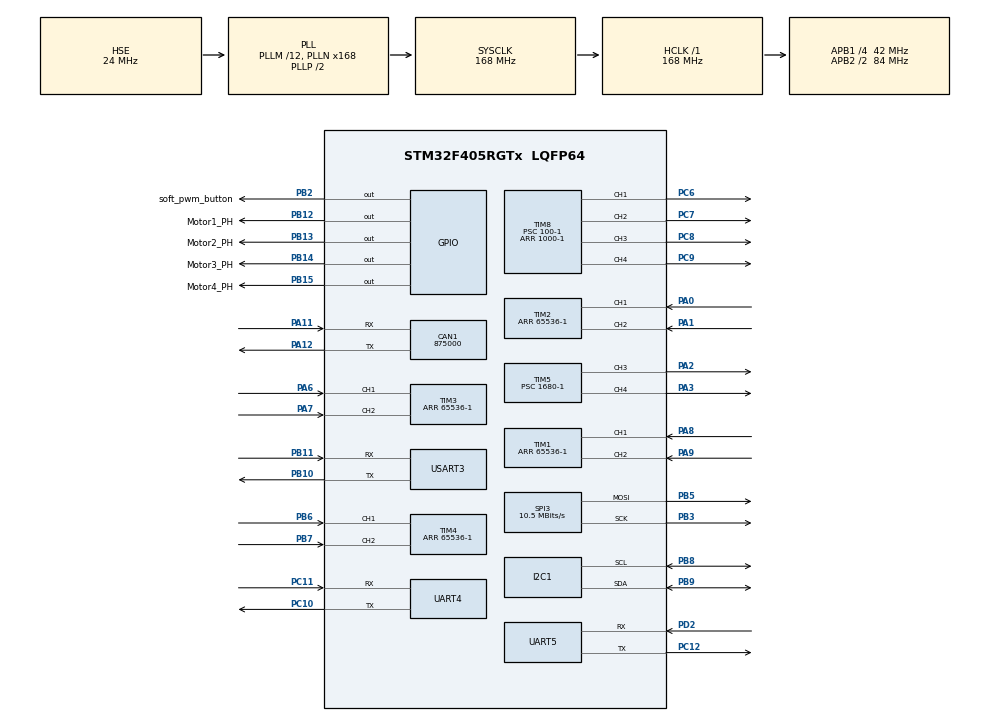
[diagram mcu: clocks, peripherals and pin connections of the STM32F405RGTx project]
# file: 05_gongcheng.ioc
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CAN1.BS1=CAN_BS1_1TQ
CAN1.BS2=CAN_BS2_1TQ
CAN1.CalculateBaudRate=875000
CAN1.CalculateTimeBit=1142
CAN1.CalculateTimeQuantum=380.95238095238096
Dma.Request0=USART3_RX
Dma.Request1=UART4_RX
Dma.Request2=UART5_RX
Dma.Request3=USART3_TX
Dma.Request4=UART4_TX
Dma.Request5=SPI3_TX
Dma.SPI3_TX.5.Direction=DMA_MEMORY_TO_PERIPH
Dma.SPI3_TX.5.FIFOMode=DMA_FIFOMODE_DISABLE
Dma.SPI3_TX.5.Instance=DMA1_Stream5
Dma.SPI3_TX.5.MemDataAlignment=DMA_MDATAALIGN_BYTE
Dma.SPI3_TX.5.MemInc=DMA_MINC_ENABLE
Dma.SPI3_TX.5.Mode=DMA_NORMAL
Dma.SPI3_TX.5.PeriphDataAlignment=DMA_PDATAALIGN_BYTE
Dma.SPI3_TX.5.PeriphInc=DMA_PINC_DISABLE
Dma.SPI3_TX.5.Priority=DMA_PRIORITY_LOW
Dma.UART4_RX.1.Direction=DMA_PERIPH_TO_MEMORY
Dma.UART4_RX.1.FIFOMode=DMA_FIFOMODE_DISABLE
Dma.UART4_RX.1.Instance=DMA1_Stream2
Dma.UART4_RX.1.MemDataAlignment=DMA_MDATAALIGN_BYTE
Dma.UART4_RX.1.MemInc=DMA_MINC_ENABLE
Dma.UART4_RX.1.Mode=DMA_NORMAL
Dma.UART4_RX.1.PeriphDataAlignment=DMA_PDATAALIGN_BYTE
Dma.UART4_RX.1.PeriphInc=DMA_PINC_DISABLE
Dma.UART4_RX.1.Priority=DMA_PRIORITY_LOW
Dma.UART4_TX.4.Direction=DMA_MEMORY_TO_PERIPH
Dma.UART4_TX.4.FIFOMode=DMA_FIFOMODE_DISABLE
Dma.UART4_TX.4.Instance=DMA1_Stream4
Dma.UART4_TX.4.MemDataAlignment=DMA_MDATAALIGN_BYTE
Dma.UART4_TX.4.MemInc=DMA_MINC_ENABLE
Dma.UART4_TX.4.Mode=DMA_NORMAL
Dma.UART4_TX.4.PeriphDataAlignment=DMA_PDATAALIGN_BYTE
Dma.UART4_TX.4.PeriphInc=DMA_PINC_DISABLE
Dma.UART4_TX.4.Priority=DMA_PRIORITY_LOW
Dma.UART5_RX.2.Direction=DMA_PERIPH_TO_MEMORY
Dma.UART5_RX.2.FIFOMode=DMA_FIFOMODE_DISABLE
Dma.UART5_RX.2.Instance=DMA1_Stream0
Dma.UART5_RX.2.MemDataAlignment=DMA_MDATAALIGN_BYTE
Dma.UART5_RX.2.MemInc=DMA_MINC_ENABLE
Dma.UART5_RX.2.Mode=DMA_NORMAL
Dma.UART5_RX.2.PeriphDataAlignment=DMA_PDATAALIGN_BYTE
Dma.UART5_RX.2.PeriphInc=DMA_PINC_DISABLE
Dma.UART5_RX.2.Priority=DMA_PRIORITY_LOW
Dma.USART3_RX.0.Direction=DMA_PERIPH_TO_MEMORY
Dma.USART3_RX.0.FIFOMode=DMA_FIFOMODE_DISABLE
Dma.USART3_RX.0.Instance=DMA1_Stream1
Dma.USART3_RX.0.MemDataAlignment=DMA_MDATAALIGN_BYTE
Dma.USART3_RX.0.MemInc=DMA_MINC_ENABLE
Dma.USART3_RX.0.Mode=DMA_NORMAL
Dma.USART3_RX.0.PeriphDataAlignment=DMA_PDATAALIGN_BYTE
Dma.USART3_RX.0.PeriphInc=DMA_PINC_DISABLE
Dma.USART3_RX.0.Priority=DMA_PRIORITY_LOW
Dma.USART3_TX.3.Direction=DMA_MEMORY_TO_PERIPH
Dma.USART3_TX.3.FIFOMode=DMA_FIFOMODE_DISABLE
Dma.USART3_TX.3.Instance=DMA1_Stream3
Dma.USART3_TX.3.MemDataAlignment=DMA_MDATAALIGN_BYTE
Dma.USART3_TX.3.MemInc=DMA_MINC_ENABLE
Dma.USART3_TX.3.Mode=DMA_NORMAL
Dma.USART3_TX.3.PeriphDataAlignment=DMA_PDATAALIGN_BYTE
Dma.USART3_TX.3.PeriphInc=DMA_PINC_DISABLE
Dma.USART3_TX.3.Priority=DMA_PRIORITY_LOW
FREERTOS.Tasks01=defaultTask,0,128,StartDefaultTask,Default,NULL,Dynamic,NULL,NULL
FREERTOS.configENABLE_FPU=1
FREERTOS.configTOTAL_HEAP_SIZE=20000
FREERTOS.configUSE_TIMERS=1
Mcu.Family=STM32F4
Mcu.Name=STM32F405RGTx
Mcu.Package=LQFP64
NVIC.DMA1_Stream0_IRQn=true\:5\:0\:false\:false\:true\:true\:false\:true\:true
NVIC.DMA1_Stream1_IRQn=true\:5\:0\:false\:false\:true\:true\:false\:true\:true
NVIC.DMA1_Stream2_IRQn=true\:5\:0\:false\:false\:true\:true\:false\:true\:true
NVIC.DMA1_Stream3_IRQn=true\:5\:0\:false\:false\:true\:true\:false\:true\:true
NVIC.DMA1_Stream4_IRQn=true\:5\:0\:false\:false\:true\:true\:false\:true\:true
NVIC.DMA1_Stream5_IRQn=true\:5\:0\:false\:false\:true\:true\:false\:true\:true
NVIC.PriorityGroup=NVIC_PRIORITYGROUP_4
NVIC.TIM1_TRG_COM_TIM11_IRQn=true\:5\:0\:false\:false\:true\:true\:true\:true\:true
NVIC.TIM8_TRG_COM_TIM14_IRQn=true\:15\:0\:false\:false\:true\:false\:false\:true\:true
NVIC.TIM8_UP_TIM13_IRQn=true\:5\:0\:false\:false\:true\:true\:true\:true\:true
NVIC.TimeBase=TIM8_TRG_COM_TIM14_IRQn
NVIC.TimeBaseIP=TIM14
NVIC.UART4_IRQn=true\:5\:0\:false\:false\:true\:true\:true\:true\:true
NVIC.UART5_IRQn=true\:5\:0\:false\:false\:true\:true\:true\:true\:true
NVIC.USART3_IRQn=true\:5\:0\:false\:false\:true\:true\:true\:true\:true
PA0-WKUP.Signal=S_TIM2_CH1_ETR
PA1.Signal=S_TIM2_CH2
PA11.Mode=CAN_Activate
PA11.Signal=CAN1_RX
PA12.Mode=CAN_Activate
PA12.Signal=CAN1_TX
PA13.Mode=Serial_Wire
PA13.Signal=SYS_JTMS-SWDIO
PA14.Mode=Serial_Wire
PA14.Signal=SYS_JTCK-SWCLK
PA2.Signal=S_TIM5_CH3
PA3.Signal=S_TIM5_CH4
PA6.Signal=S_TIM3_CH1
PA7.Signal=S_TIM3_CH2
PA8.Signal=S_TIM1_CH1
PA9.Signal=S_TIM1_CH2
PB10.Mode=Asynchronous
PB10.Signal=USART3_TX
PB11.Mode=Asynchronous
PB11.Signal=USART3_RX
PB12.GPIO_Label=Motor1_PH
PB12.Signal=GPIO_Output
PB13.GPIO_Label=Motor2_PH
PB13.Signal=GPIO_Output
PB14.GPIO_Label=Motor3_PH
PB14.Signal=GPIO_Output
PB15.GPIO_Label=Motor4_PH
PB15.Signal=GPIO_Output
PB2.GPIO_Label=soft_pwm_button
PB2.Signal=GPIO_Output
PB3.Mode=TX_Only_Simplex_Unidirect_Master
PB3.Signal=SPI3_SCK
PB5.Mode=TX_Only_Simplex_Unidirect_Master
PB5.Signal=SPI3_MOSI
PB6.Signal=S_TIM4_CH1
PB7.Signal=S_TIM4_CH2
PB8.Mode=I2C
PB8.Signal=I2C1_SCL
PB9.Mode=I2C
PB9.Signal=I2C1_SDA
PC10.Mode=Asynchronous
PC10.Signal=UART4_TX
PC11.Mode=Asynchronous
PC11.Signal=UART4_RX
PC12.Mode=Asynchronous
PC12.Signal=UART5_TX
PC6.GPIO_PuPd=GPIO_PULLDOWN
PC6.Signal=S_TIM8_CH1
PC7.GPIO_PuPd=GPIO_PULLDOWN
PC7.Signal=S_TIM8_CH2
PC8.GPIO_PuPd=GPIO_PULLDOWN
PC8.Signal=S_TIM8_CH3
PC9.GPIO_PuPd=GPIO_PULLDOWN
PC9.Signal=S_TIM8_CH4
PD2.Mode=Asynchronous
PD2.Signal=UART5_RX
PH0-OSC_IN.Mode=HSE-External-Oscillator
PH0-OSC_IN.Signal=RCC_OSC_IN
PH1-OSC_OUT.Mode=HSE-External-Oscillator
PH1-OSC_OUT.Signal=RCC_OSC_OUT
ProjectManager.HeapSize=0x5000
ProjectManager.StackSize=0x7000
ProjectManager.TargetToolchain=MDK-ARM V5.32
RCC.48MHZClocksFreq_Value=84000000
RCC.AHBFreq_Value=168000000
RCC.APB1CLKDivider=RCC_HCLK_DIV4
RCC.APB1Freq_Value=42000000
RCC.APB1TimFreq_Value=84000000
RCC.APB2CLKDivider=RCC_HCLK_DIV2
RCC.APB2Freq_Value=84000000
RCC.APB2TimFreq_Value=168000000
RCC.CortexFreq_Value=168000000
RCC.HCLKFreq_Value=168000000
RCC.HSE_VALUE=24000000
RCC.HSI_VALUE=16000000
RCC.LSE_VALUE=32768
RCC.PLLM=12
RCC.PLLN=168
RCC.PLLSourceVirtual=RCC_PLLSOURCE_HSE
RCC.RCC_RTC_Clock_Source=RCC_RTCCLKSOURCE_LSI
RCC.RCC_RTC_Clock_SourceVirtual=RCC_RTCCLKSOURCE_LSI
RCC.SYSCLKFreq_VALUE=168000000
RCC.SYSCLKSource=RCC_SYSCLKSOURCE_PLLCLK
RCC.VCOOutputFreq_Value=336000000
SH.S_TIM1_CH1.0=TIM1_CH1,Encoder_Interface
SH.S_TIM1_CH2.0=TIM1_CH2,Encoder_Interface
SH.S_TIM2_CH1_ETR.0=TIM2_CH1,Encoder_Interface
SH.S_TIM2_CH2.0=TIM2_CH2,Encoder_Interface
SH.S_TIM3_CH1.0=TIM3_CH1,Encoder_Interface
SH.S_TIM3_CH2.0=TIM3_CH2,Encoder_Interface
SH.S_TIM4_CH1.0=TIM4_CH1,Encoder_Interface
SH.S_TIM4_CH2.0=TIM4_CH2,Encoder_Interface
SH.S_TIM5_CH3.0=TIM5_CH3,PWM Generation3 CH3
SH.S_TIM5_CH4.0=TIM5_CH4,PWM Generation4 CH4
SH.S_TIM8_CH1.0=TIM8_CH1,PWM Generation1 CH1
SH.S_TIM8_CH2.0=TIM8_CH2,PWM Generation2 CH2
SH.S_TIM8_CH3.0=TIM8_CH3,PWM Generation3 CH3
SH.S_TIM8_CH4.0=TIM8_CH4,PWM Generation4 CH4
SPI3.BaudRatePrescaler=SPI_BAUDRATEPRESCALER_4
SPI3.CalculateBaudRate=10.5 MBits/s
SPI3.Direction=SPI_DIRECTION_2LINES
SPI3.Mode=SPI_MODE_MASTER
SPI3.VirtualType=VM_MASTER
TIM1.EncoderMode=TIM_ENCODERMODE_TI12
TIM1.Period=65536-1
TIM11.Period=1000-1
TIM11.Prescaler=3360-1
TIM13.AutoReloadPreload=TIM_AUTORELOAD_PRELOAD_ENABLE
TIM13.Period=100-1
TIM13.Prescaler=84-1
TIM2.EncoderMode=TIM_ENCODERMODE_TI12
TIM2.Period=65536-1
TIM3.EncoderMode=TIM_ENCODERMODE_TI12
TIM3.Period=65536-1
TIM4.EncoderMode=TIM_ENCODERMODE_TI12
TIM4.Period=65536-1
TIM5.Channel-PWM\ Generation3\ CH3=TIM_CHANNEL_3
TIM5.Channel-PWM\ Generation4\ CH4=TIM_CHANNEL_4
TIM5.Period=1000-1
TIM5.Prescaler=1680-1
TIM8.Channel-PWM\ Generation1\ CH1=TIM_CHANNEL_1
TIM8.Channel-PWM\ Generation2\ CH2=TIM_CHANNEL_2
TIM8.Channel-PWM\ Generation3\ CH3=TIM_CHANNEL_3
TIM8.Channel-PWM\ Generation4\ CH4=TIM_CHANNEL_4
TIM8.Period=1000-1
TIM8.Prescaler=100-1
UART4.VirtualMode=Asynchronous
UART5.VirtualMode=Asynchronous
USART3.VirtualMode=VM_ASYNC
VP_FREERTOS_VS_CMSIS_V1.Mode=CMSIS_V1
VP_SYS_VS_tim14.Mode=TIM14
VP_TIM11_VS_ClockSourceINT.Mode=Enable_Timer
VP_TIM13_VS_ClockSourceINT.Mode=Enable_Timer
VP_TIM5_VS_ClockSourceINT.Mode=Internal
VP_TIM8_VS_ClockSourceINT.Mode=Internal
board=custom

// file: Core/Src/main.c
/* USER CODE BEGIN Header */
/**
 ******************************************************************************
 * @file           : main.c
 * @brief          : Main program body
 ******************************************************************************
 * @attention
 *
 * Copyright (c) 2024 STMicroelectronics.
 * All rights reserved.
 *
 * This software is licensed under terms that can be found in the LICENSE file
 * in the root directory of this software component.
 * If no LICENSE file comes with this software, it is provided AS-IS.
 *
 ******************************************************************************
 */
/* USER CODE END Header */
#include "main.h"
#include "cmsis_os.h"

/* USER CODE BEGIN Includes */
#include "maincpp.h"
#include <stdarg.h>
#include "string.h"
#include "soft_pwm.h"
/* USER CODE END Includes */

CAN_HandleTypeDef hcan1;

I2C_HandleTypeDef hi2c1;

SPI_HandleTypeDef hspi3;
DMA_HandleTypeDef hdma_spi3_tx;

TIM_HandleTypeDef htim1;
TIM_HandleTypeDef htim2;
TIM_HandleTypeDef htim3;
TIM_HandleTypeDef htim4;
TIM_HandleTypeDef htim5;
TIM_HandleTypeDef htim8;
TIM_HandleTypeDef htim11;
TIM_HandleTypeDef htim13;

UART_HandleTypeDef huart4;
UART_HandleTypeDef huart5;
UART_HandleTypeDef huart3;
DMA_HandleTypeDef hdma_uart4_rx;
DMA_HandleTypeDef hdma_uart4_tx;
DMA_HandleTypeDef hdma_uart5_rx;
DMA_HandleTypeDef hdma_usart3_rx;
DMA_HandleTypeDef hdma_usart3_tx;

osThreadId defaultTaskHandle;

void SystemClock_Config(void);
static void MX_GPIO_Init(void);
static void MX_DMA_Init(void);
static void MX_TIM1_Init(void);
static void MX_TIM2_Init(void);
static void MX_TIM3_Init(void);
static void MX_TIM4_Init(void);
static void MX_TIM8_Init(void);
static void MX_TIM5_Init(void);
static void MX_TIM11_Init(void);
static void MX_USART3_UART_Init(void);
static void MX_CAN1_Init(void);
static void MX_I2C1_Init(void);
static void MX_SPI3_Init(void);
static void MX_TIM13_Init(void);
static void MX_UART4_Init(void);
static void MX_UART5_Init(void);
void StartDefaultTask(void const * argument);

int main(void)
{

  /* MCU Configuration--------------------------------------------------------*/

  /* Reset of all peripherals, Initializes the Flash interface and the Systick. */
  HAL_Init();

  /* Configure the system clock */
  SystemClock_Config();

  /* Initialize all configured peripherals */
  MX_GPIO_Init();
  MX_DMA_Init();
  MX_TIM1_Init();
  MX_TIM2_Init();
  MX_TIM3_Init();
  MX_TIM4_Init();
  MX_TIM8_Init();
  MX_TIM5_Init();
  MX_TIM11_Init();
  MX_USART3_UART_Init();
  MX_CAN1_Init();
  MX_I2C1_Init();
  MX_SPI3_Init();
  MX_TIM13_Init();
  MX_UART4_Init();
  MX_UART5_Init();
  /* USER CODE BEGIN 2 */
	HAL_Delay(6000);
  main_cpp();
  /* USER CODE END 2 */

  /* Create the thread(s) */
  /* definition and creation of defaultTask */
  osThreadDef(defaultTask, StartDefaultTask, osPriorityNormal, 0, 128);
  defaultTaskHandle = osThreadCreate(osThread(defaultTask), NULL);

  /* Start scheduler */
  osKernelStart();

  /* We should never get here as control is now taken by the scheduler */

  /* Infinite loop */
  while (1)
  {

  }
}

void SystemClock_Config(void)
{
  RCC_OscInitTypeDef RCC_OscInitStruct = {0};
  RCC_ClkInitTypeDef RCC_ClkInitStruct = {0};

  /** Configure the main internal regulator output voltage
  */
  __HAL_RCC_PWR_CLK_ENABLE();
  __HAL_PWR_VOLTAGESCALING_CONFIG(PWR_REGULATOR_VOLTAGE_SCALE1);

  /** Initializes the RCC Oscillators according to the specified parameters
  * in the RCC_OscInitTypeDef structure.
  */
  RCC_OscInitStruct.OscillatorType = RCC_OSCILLATORTYPE_HSE;
  RCC_OscInitStruct.HSEState = RCC_HSE_ON;
  RCC_OscInitStruct.PLL.PLLState = RCC_PLL_ON;
  RCC_OscInitStruct.PLL.PLLSource = RCC_PLLSOURCE_HSE;
  RCC_OscInitStruct.PLL.PLLM = 12;
  RCC_OscInitStruct.PLL.PLLN = 168;
  RCC_OscInitStruct.PLL.PLLP = RCC_PLLP_DIV2;
  RCC_OscInitStruct.PLL.PLLQ = 4;
  if (HAL_RCC_OscConfig(&RCC_OscInitStruct) != HAL_OK)
  {
    Error_Handler();
  }

  /** Initializes the CPU, AHB and APB buses clocks
  */
  RCC_ClkInitStruct.ClockType = RCC_CLOCKTYPE_HCLK|RCC_CLOCKTYPE_SYSCLK
                              |RCC_CLOCKTYPE_PCLK1|RCC_CLOCKTYPE_PCLK2;
  RCC_ClkInitStruct.SYSCLKSource = RCC_SYSCLKSOURCE_PLLCLK;
  RCC_ClkInitStruct.AHBCLKDivider = RCC_SYSCLK_DIV1;
  RCC_ClkInitStruct.APB1CLKDivider = RCC_HCLK_DIV4;
  RCC_ClkInitStruct.APB2CLKDivider = RCC_HCLK_DIV2;

  if (HAL_RCC_ClockConfig(&RCC_ClkInitStruct, FLASH_LATENCY_5) != HAL_OK)
  {
    Error_Handler();
  }
}

static void MX_CAN1_Init(void)
{

  hcan1.Instance = CAN1;
  hcan1.Init.Prescaler = 16;
  hcan1.Init.Mode = CAN_MODE_NORMAL;
  hcan1.Init.SyncJumpWidth = CAN_SJW_1TQ;
  hcan1.Init.TimeSeg1 = CAN_BS1_1TQ;
  hcan1.Init.TimeSeg2 = CAN_BS2_1TQ;
  hcan1.Init.TimeTriggeredMode = DISABLE;
  hcan1.Init.AutoBusOff = DISABLE;
  hcan1.Init.AutoWakeUp = DISABLE;
  hcan1.Init.AutoRetransmission = DISABLE;
  hcan1.Init.ReceiveFifoLocked = DISABLE;
  hcan1.Init.TransmitFifoPriority = DISABLE;
  if (HAL_CAN_Init(&hcan1) != HAL_OK)
  {
    Error_Handler();
  }

}

static void MX_I2C1_Init(void)
{

  hi2c1.Instance = I2C1;
  hi2c1.Init.ClockSpeed = 100000;
  hi2c1.Init.DutyCycle = I2C_DUTYCYCLE_2;
  hi2c1.Init.OwnAddress1 = 0;
  hi2c1.Init.AddressingMode = I2C_ADDRESSINGMODE_7BIT;
  hi2c1.Init.DualAddressMode = I2C_DUALADDRESS_DISABLE;
  hi2c1.Init.OwnAddress2 = 0;
  hi2c1.Init.GeneralCallMode = I2C_GENERALCALL_DISABLE;
  hi2c1.Init.NoStretchMode = I2C_NOSTRETCH_DISABLE;
  if (HAL_I2C_Init(&hi2c1) != HAL_OK)
  {
    Error_Handler();
  }

}

static void MX_SPI3_Init(void)
{

  /* SPI3 parameter configuration*/
  hspi3.Instance = SPI3;
  hspi3.Init.Mode = SPI_MODE_MASTER;
  hspi3.Init.Direction = SPI_DIRECTION_2LINES;
  hspi3.Init.DataSize = SPI_DATASIZE_8BIT;
  hspi3.Init.CLKPolarity = SPI_POLARITY_LOW;
  hspi3.Init.CLKPhase = SPI_PHASE_1EDGE;
  hspi3.Init.NSS = SPI_NSS_SOFT;
  hspi3.Init.BaudRatePrescaler = SPI_BAUDRATEPRESCALER_4;
  hspi3.Init.FirstBit = SPI_FIRSTBIT_MSB;
  hspi3.Init.TIMode = SPI_TIMODE_DISABLE;
  hspi3.Init.CRCCalculation = SPI_CRCCALCULATION_DISABLE;
  hspi3.Init.CRCPolynomial = 10;
  if (HAL_SPI_Init(&hspi3) != HAL_OK)
  {
    Error_Handler();
  }

}

static void MX_TIM1_Init(void)
{

  TIM_Encoder_InitTypeDef sConfig = {0};
  TIM_MasterConfigTypeDef sMasterConfig = {0};

  htim1.Instance = TIM1;
  htim1.Init.Prescaler = 0;
  htim1.Init.CounterMode = TIM_COUNTERMODE_UP;
  htim1.Init.Period = 65536-1;
  htim1.Init.ClockDivision = TIM_CLOCKDIVISION_DIV1;
  htim1.Init.RepetitionCounter = 0;
  htim1.Init.AutoReloadPreload = TIM_AUTORELOAD_PRELOAD_DISABLE;
  sConfig.EncoderMode = TIM_ENCODERMODE_TI12;
  sConfig.IC1Polarity = TIM_ICPOLARITY_RISING;
  sConfig.IC1Selection = TIM_ICSELECTION_DIRECTTI;
  sConfig.IC1Prescaler = TIM_ICPSC_DIV1;
  sConfig.IC1Filter = 0;
  sConfig.IC2Polarity = TIM_ICPOLARITY_RISING;
  sConfig.IC2Selection = TIM_ICSELECTION_DIRECTTI;
  sConfig.IC2Prescaler = TIM_ICPSC_DIV1;
  sConfig.IC2Filter = 0;
  if (HAL_TIM_Encoder_Init(&htim1, &sConfig) != HAL_OK)
  {
    Error_Handler();
  }
  sMasterConfig.MasterOutputTrigger = TIM_TRGO_RESET;
  sMasterConfig.MasterSlaveMode = TIM_MASTERSLAVEMODE_DISABLE;
  if (HAL_TIMEx_MasterConfigSynchronization(&htim1, &sMasterConfig) != HAL_OK)
  {
    Error_Handler();
  }

}

static void MX_TIM2_Init(void)
{

  TIM_Encoder_InitTypeDef sConfig = {0};
  TIM_MasterConfigTypeDef sMasterConfig = {0};

  htim2.Instance = TIM2;
  htim2.Init.Prescaler = 0;
  htim2.Init.CounterMode = TIM_COUNTERMODE_UP;
  htim2.Init.Period = 65536-1;
  htim2.Init.ClockDivision = TIM_CLOCKDIVISION_DIV1;
  htim2.Init.AutoReloadPreload = TIM_AUTORELOAD_PRELOAD_DISABLE;
  sConfig.EncoderMode = TIM_ENCODERMODE_TI12;
  sConfig.IC1Polarity = TIM_ICPOLARITY_RISING;
  sConfig.IC1Selection = TIM_ICSELECTION_DIRECTTI;
  sConfig.IC1Prescaler = TIM_ICPSC_DIV1;
  sConfig.IC1Filter = 0;
  sConfig.IC2Polarity = TIM_ICPOLARITY_RISING;
  sConfig.IC2Selection = TIM_ICSELECTION_DIRECTTI;
  sConfig.IC2Prescaler = TIM_ICPSC_DIV1;
  sConfig.IC2Filter = 0;
  if (HAL_TIM_Encoder_Init(&htim2, &sConfig) != HAL_OK)
  {
    Error_Handler();
  }
  sMasterConfig.MasterOutputTrigger = TIM_TRGO_RESET;
  sMasterConfig.MasterSlaveMode = TIM_MASTERSLAVEMODE_DISABLE;
  if (HAL_TIMEx_MasterConfigSynchronization(&htim2, &sMasterConfig) != HAL_OK)
  {
    Error_Handler();
  }

}

static void MX_TIM3_Init(void)
{

  TIM_Encoder_InitTypeDef sConfig = {0};
  TIM_MasterConfigTypeDef sMasterConfig = {0};

  htim3.Instance = TIM3;
  htim3.Init.Prescaler = 0;
  htim3.Init.CounterMode = TIM_COUNTERMODE_UP;
  htim3.Init.Period = 65536-1;
  htim3.Init.ClockDivision = TIM_CLOCKDIVISION_DIV1;
  htim3.Init.AutoReloadPreload = TIM_AUTORELOAD_PRELOAD_DISABLE;
  sConfig.EncoderMode = TIM_ENCODERMODE_TI12;
  sConfig.IC1Polarity = TIM_ICPOLARITY_RISING;
  sConfig.IC1Selection = TIM_ICSELECTION_DIRECTTI;
  sConfig.IC1Prescaler = TIM_ICPSC_DIV1;
  sConfig.IC1Filter = 0;
  sConfig.IC2Polarity = TIM_ICPOLARITY_RISING;
  sConfig.IC2Selection = TIM_ICSELECTION_DIRECTTI;
  sConfig.IC2Prescaler = TIM_ICPSC_DIV1;
  sConfig.IC2Filter = 0;
  if (HAL_TIM_Encoder_Init(&htim3, &sConfig) != HAL_OK)
  {
    Error_Handler();
  }
  sMasterConfig.MasterOutputTrigger = TIM_TRGO_RESET;
  sMasterConfig.MasterSlaveMode = TIM_MASTERSLAVEMODE_DISABLE;
  if (HAL_TIMEx_MasterConfigSynchronization(&htim3, &sMasterConfig) != HAL_OK)
  {
    Error_Handler();
  }

}

static void MX_TIM4_Init(void)
{

  TIM_Encoder_InitTypeDef sConfig = {0};
  TIM_MasterConfigTypeDef sMasterConfig = {0};

  htim4.Instance = TIM4;
  htim4.Init.Prescaler = 0;
  htim4.Init.CounterMode = TIM_COUNTERMODE_UP;
  htim4.Init.Period = 65536-1;
  htim4.Init.ClockDivision = TIM_CLOCKDIVISION_DIV1;
  htim4.Init.AutoReloadPreload = TIM_AUTORELOAD_PRELOAD_DISABLE;
  sConfig.EncoderMode = TIM_ENCODERMODE_TI12;
  sConfig.IC1Polarity = TIM_ICPOLARITY_RISING;
  sConfig.IC1Selection = TIM_ICSELECTION_DIRECTTI;
  sConfig.IC1Prescaler = TIM_ICPSC_DIV1;
  sConfig.IC1Filter = 0;
  sConfig.IC2Polarity = TIM_ICPOLARITY_RISING;
  sConfig.IC2Selection = TIM_ICSELECTION_DIRECTTI;
  sConfig.IC2Prescaler = TIM_ICPSC_DIV1;
  sConfig.IC2Filter = 0;
  if (HAL_TIM_Encoder_Init(&htim4, &sConfig) != HAL_OK)
  {
    Error_Handler();
  }
  sMasterConfig.MasterOutputTrigger = TIM_TRGO_RESET;
  sMasterConfig.MasterSlaveMode = TIM_MASTERSLAVEMODE_DISABLE;
  if (HAL_TIMEx_MasterConfigSynchronization(&htim4, &sMasterConfig) != HAL_OK)
  {
    Error_Handler();
  }

}

static void MX_TIM5_Init(void)
{

  TIM_ClockConfigTypeDef sClockSourceConfig = {0};
  TIM_MasterConfigTypeDef sMasterConfig = {0};
  TIM_OC_InitTypeDef sConfigOC = {0};

  htim5.Instance = TIM5;
  htim5.Init.Prescaler = 1680-1;
  htim5.Init.CounterMode = TIM_COUNTERMODE_UP;
  htim5.Init.Period = 1000-1;
  htim5.Init.ClockDivision = TIM_CLOCKDIVISION_DIV1;
  htim5.Init.AutoReloadPreload = TIM_AUTORELOAD_PRELOAD_DISABLE;
  if (HAL_TIM_Base_Init(&htim5) != HAL_OK)
  {
    Error_Handler();
  }
  sClockSourceConfig.ClockSource = TIM_CLOCKSOURCE_INTERNAL;
  if (HAL_TIM_ConfigClockSource(&htim5, &sClockSourceConfig) != HAL_OK)
  {
    Error_Handler();
  }
  if (HAL_TIM_PWM_Init(&htim5) != HAL_OK)
  {
    Error_Handler();
  }
  sMasterConfig.MasterOutputTrigger = TIM_TRGO_RESET;
  sMasterConfig.MasterSlaveMode = TIM_MASTERSLAVEMODE_DISABLE;
  if (HAL_TIMEx_MasterConfigSynchronization(&htim5, &sMasterConfig) != HAL_OK)
  {
    Error_Handler();
  }
  sConfigOC.OCMode = TIM_OCMODE_PWM1;
  sConfigOC.Pulse = 0;
  sConfigOC.OCPolarity = TIM_OCPOLARITY_HIGH;
  sConfigOC.OCFastMode = TIM_OCFAST_DISABLE;
  if (HAL_TIM_PWM_ConfigChannel(&htim5, &sConfigOC, TIM_CHANNEL_3) != HAL_OK)
  {
    Error_Handler();
  }
  if (HAL_TIM_PWM_ConfigChannel(&htim5, &sConfigOC, TIM_CHANNEL_4) != HAL_OK)
  {
    Error_Handler();
  }
  HAL_TIM_MspPostInit(&htim5);

}

static void MX_TIM8_Init(void)
{

  TIM_ClockConfigTypeDef sClockSourceConfig = {0};
  TIM_MasterConfigTypeDef sMasterConfig = {0};
  TIM_OC_InitTypeDef sConfigOC = {0};
  TIM_BreakDeadTimeConfigTypeDef sBreakDeadTimeConfig = {0};

  htim8.Instance = TIM8;
  htim8.Init.Prescaler = 100-1;
  htim8.Init.CounterMode = TIM_COUNTERMODE_UP;
  htim8.Init.Period = 1000-1;
  htim8.Init.ClockDivision = TIM_CLOCKDIVISION_DIV1;
  htim8.Init.RepetitionCounter = 0;
  htim8.Init.AutoReloadPreload = TIM_AUTORELOAD_PRELOAD_DISABLE;
  if (HAL_TIM_Base_Init(&htim8) != HAL_OK)
  {
    Error_Handler();
  }
  sClockSourceConfig.ClockSource = TIM_CLOCKSOURCE_INTERNAL;
  if (HAL_TIM_ConfigClockSource(&htim8, &sClockSourceConfig) != HAL_OK)
  {
    Error_Handler();
  }
  if (HAL_TIM_PWM_Init(&htim8) != HAL_OK)
  {
    Error_Handler();
  }
  sMasterConfig.MasterOutputTrigger = TIM_TRGO_RESET;
  sMasterConfig.MasterSlaveMode = TIM_MASTERSLAVEMODE_DISABLE;
  if (HAL_TIMEx_MasterConfigSynchronization(&htim8, &sMasterConfig) != HAL_OK)
  {
    Error_Handler();
  }
  sConfigOC.OCMode = TIM_OCMODE_PWM1;
  sConfigOC.Pulse = 0;
  sConfigOC.OCPolarity = TIM_OCPOLARITY_HIGH;
  sConfigOC.OCNPolarity = TIM_OCNPOLARITY_HIGH;
  sConfigOC.OCFastMode = TIM_OCFAST_DISABLE;
  sConfigOC.OCIdleState = TIM_OCIDLESTATE_RESET;
  sConfigOC.OCNIdleState = TIM_OCNIDLESTATE_RESET;
  if (HAL_TIM_PWM_ConfigChannel(&htim8, &sConfigOC, TIM_CHANNEL_1) != HAL_OK)
  {
    Error_Handler();
  }
  if (HAL_TIM_PWM_ConfigChannel(&htim8, &sConfigOC, TIM_CHANNEL_2) != HAL_OK)
  {
    Error_Handler();
  }
  if (HAL_TIM_PWM_ConfigChannel(&htim8, &sConfigOC, TIM_CHANNEL_3) != HAL_OK)
  {
    Error_Handler();
  }
  if (HAL_TIM_PWM_ConfigChannel(&htim8, &sConfigOC, TIM_CHANNEL_4) != HAL_OK)
  {
    Error_Handler();
  }
  sBreakDeadTimeConfig.OffStateRunMode = TIM_OSSR_DISABLE;
  sBreakDeadTimeConfig.OffStateIDLEMode = TIM_OSSI_DISABLE;
  sBreakDeadTimeConfig.LockLevel = TIM_LOCKLEVEL_OFF;
  sBreakDeadTimeConfig.DeadTime = 0;
  sBreakDeadTimeConfig.BreakState = TIM_BREAK_DISABLE;
  sBreakDeadTimeConfig.BreakPolarity = TIM_BREAKPOLARITY_HIGH;
  sBreakDeadTimeConfig.AutomaticOutput = TIM_AUTOMATICOUTPUT_DISABLE;
  if (HAL_TIMEx_ConfigBreakDeadTime(&htim8, &sBreakDeadTimeConfig) != HAL_OK)
  {
    Error_Handler();
  }
  HAL_TIM_MspPostInit(&htim8);

}

static void MX_TIM11_Init(void)
{

  htim11.Instance = TIM11;
  htim11.Init.Prescaler = 3360-1;
  htim11.Init.CounterMode = TIM_COUNTERMODE_UP;
  htim11.Init.Period = 1000-1;
  htim11.Init.ClockDivision = TIM_CLOCKDIVISION_DIV1;
  htim11.Init.AutoReloadPreload = TIM_AUTORELOAD_PRELOAD_DISABLE;
  if (HAL_TIM_Base_Init(&htim11) != HAL_OK)
  {
    Error_Handler();
  }

}

static void MX_TIM13_Init(void)
{

  htim13.Instance = TIM13;
  htim13.Init.Prescaler = 84-1;
  htim13.Init.CounterMode = TIM_COUNTERMODE_UP;
  htim13.Init.Period = 100-1;
  htim13.Init.ClockDivision = TIM_CLOCKDIVISION_DIV1;
  htim13.Init.AutoReloadPreload = TIM_AUTORELOAD_PRELOAD_ENABLE;
  if (HAL_TIM_Base_Init(&htim13) != HAL_OK)
  {
    Error_Handler();
  }

}

static void MX_UART4_Init(void)
{

  huart4.Instance = UART4;
  huart4.Init.BaudRate = 115200;
  huart4.Init.WordLength = UART_WORDLENGTH_8B;
  huart4.Init.StopBits = UART_STOPBITS_1;
  huart4.Init.Parity = UART_PARITY_NONE;
  huart4.Init.Mode = UART_MODE_TX_RX;
  huart4.Init.HwFlowCtl = UART_HWCONTROL_NONE;
  huart4.Init.OverSampling = UART_OVERSAMPLING_16;
  if (HAL_UART_Init(&huart4) != HAL_OK)
  {
    Error_Handler();
  }

}

static void MX_UART5_Init(void)
{

  huart5.Instance = UART5;
  huart5.Init.BaudRate = 115200;
  huart5.Init.WordLength = UART_WORDLENGTH_8B;
  huart5.Init.StopBits = UART_STOPBITS_1;
  huart5.Init.Parity = UART_PARITY_NONE;
  huart5.Init.Mode = UART_MODE_TX_RX;
  huart5.Init.HwFlowCtl = UART_HWCONTROL_NONE;
  huart5.Init.OverSampling = UART_OVERSAMPLING_16;
  if (HAL_UART_Init(&huart5) != HAL_OK)
  {
    Error_Handler();
  }

}

static void MX_USART3_UART_Init(void)
{

  huart3.Instance = USART3;
  huart3.Init.BaudRate = 115200;
  huart3.Init.WordLength = UART_WORDLENGTH_8B;
  huart3.Init.StopBits = UART_STOPBITS_1;
  huart3.Init.Parity = UART_PARITY_NONE;
  huart3.Init.Mode = UART_MODE_TX_RX;
  huart3.Init.HwFlowCtl = UART_HWCONTROL_NONE;
  huart3.Init.OverSampling = UART_OVERSAMPLING_16;
  if (HAL_UART_Init(&huart3) != HAL_OK)
  {
    Error_Handler();
  }

}

static void MX_DMA_Init(void)
{

  /* DMA controller clock enable */
  __HAL_RCC_DMA1_CLK_ENABLE();

  /* DMA interrupt init */
  /* DMA1_Stream0_IRQn interrupt configuration */
  HAL_NVIC_SetPriority(DMA1_Stream0_IRQn, 5, 0);
  HAL_NVIC_EnableIRQ(DMA1_Stream0_IRQn);
  /* DMA1_Stream1_IRQn interrupt configuration */
  HAL_NVIC_SetPriority(DMA1_Stream1_IRQn, 5, 0);
  HAL_NVIC_EnableIRQ(DMA1_Stream1_IRQn);
  /* DMA1_Stream2_IRQn interrupt configuration */
  HAL_NVIC_SetPriority(DMA1_Stream2_IRQn, 5, 0);
  HAL_NVIC_EnableIRQ(DMA1_Stream2_IRQn);
  /* DMA1_Stream3_IRQn interrupt configuration */
  HAL_NVIC_SetPriority(DMA1_Stream3_IRQn, 5, 0);
  HAL_NVIC_EnableIRQ(DMA1_Stream3_IRQn);
  /* DMA1_Stream4_IRQn interrupt configuration */
  HAL_NVIC_SetPriority(DMA1_Stream4_IRQn, 5, 0);
  HAL_NVIC_EnableIRQ(DMA1_Stream4_IRQn);
  /* DMA1_Stream5_IRQn interrupt configuration */
  HAL_NVIC_SetPriority(DMA1_Stream5_IRQn, 5, 0);
  HAL_NVIC_EnableIRQ(DMA1_Stream5_IRQn);

}

static void MX_GPIO_Init(void)
{
  GPIO_InitTypeDef GPIO_InitStruct = {0};

  /* GPIO Ports Clock Enable */
  __HAL_RCC_GPIOH_CLK_ENABLE();
  __HAL_RCC_GPIOA_CLK_ENABLE();
  __HAL_RCC_GPIOB_CLK_ENABLE();
  __HAL_RCC_GPIOC_CLK_ENABLE();
  __HAL_RCC_GPIOD_CLK_ENABLE();

  /*Configure GPIO pin Output Level */
  HAL_GPIO_WritePin(GPIOB, soft_pwm_button_Pin|Motor1_PH_Pin|Motor2_PH_Pin|Motor3_PH_Pin
                          |Motor4_PH_Pin, GPIO_PIN_RESET);

  /*Configure GPIO pins : soft_pwm_button_Pin Motor1_PH_Pin Motor2_PH_Pin Motor3_PH_Pin
                           Motor4_PH_Pin */
  GPIO_InitStruct.Pin = soft_pwm_button_Pin|Motor1_PH_Pin|Motor2_PH_Pin|Motor3_PH_Pin
                          |Motor4_PH_Pin;
  GPIO_InitStruct.Mode = GPIO_MODE_OUTPUT_PP;
  GPIO_InitStruct.Pull = GPIO_NOPULL;
  GPIO_InitStruct.Speed = GPIO_SPEED_FREQ_LOW;
  HAL_GPIO_Init(GPIOB, &GPIO_InitStruct);

}

void StartDefaultTask(void const * argument)
{
  for(;;)
  {
    osDelay(1);
  }
}

void HAL_TIM_PeriodElapsedCallback(TIM_HandleTypeDef *htim)
{
  if (htim->Instance == TIM14)
  {
    HAL_IncTick();
  }
  /* USER CODE BEGIN Callback 1 */
if(htim->Instance == TIM13)
{
SoftPwmTimerISR() ;
}
  /* USER CODE END Callback 1 */
}

void Error_Handler(void)
{
  __disable_irq();
  while (1)
  {
  }
}
